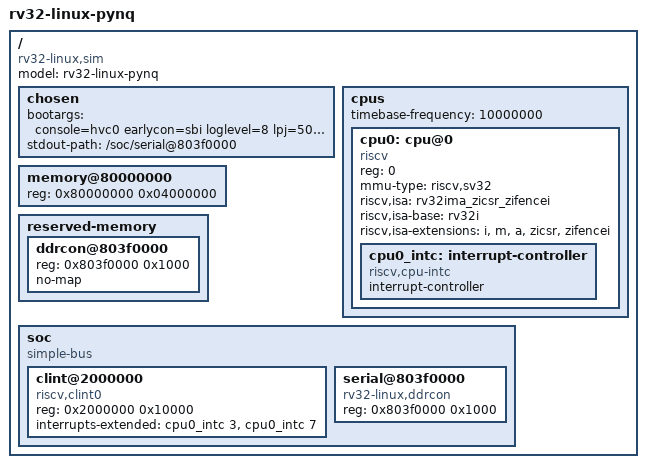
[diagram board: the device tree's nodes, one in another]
/dts-v1/;

/ {
	#address-cells = <1>;
	#size-cells = <1>;
	compatible = "rv32-linux,sim";
	model = "rv32-linux-pynq";

	chosen {
		bootargs = "console=hvc0 earlycon=sbi loglevel=8 lpj=500000";
		stdout-path = "/soc/serial@803f0000";
	};

	cpus {
		#address-cells = <1>;
		#size-cells = <0>;
		timebase-frequency = <10000000>;

		cpu0: cpu@0 {
			device_type = "cpu";
			compatible = "riscv";
			reg = <0>;
			status = "okay";
			mmu-type = "riscv,sv32";
			riscv,isa = "rv32ima_zicsr_zifencei";
			riscv,isa-base = "rv32i";
			riscv,isa-extensions = "i", "m", "a", "zicsr", "zifencei";

			cpu0_intc: interrupt-controller {
				#interrupt-cells = <1>;
				compatible = "riscv,cpu-intc";
				interrupt-controller;
			};
		};
	};

	memory@80000000 {
		device_type = "memory";
		reg = <0x80000000 0x04000000>;
	};

	reserved-memory {
		#address-cells = <1>;
		#size-cells = <1>;
		ranges;
		ddrcon@803f0000 {
			reg = <0x803f0000 0x1000>;
			no-map;
		};
	};

	soc {
		#address-cells = <1>;
		#size-cells = <1>;
		compatible = "simple-bus";
		ranges;

		clint@2000000 {
			compatible = "riscv,clint0";
			reg = <0x2000000 0x10000>;
			interrupts-extended = <&cpu0_intc 3>, <&cpu0_intc 7>;
		};

		serial@803f0000 {
			compatible = "rv32-linux,ddrcon";
			reg = <0x803f0000 0x1000>;
		};
	};
};
